# EFR32FG1V131F256GM48 register map
File version: 3.0.0
CPU: CM4 r0p1, little endian, MPU, FPU, 3 interrupt priority bits
Registers are 32-bit, read-write, reset 0x0 unless marked. A register's access mark holds for its fields unless they carry their own. Offsets are from the block's base; [hi:lo] are bit positions; {n}, {i} and the like mark numbered series; 'fields as' and 'values as' point back to an identical list.

## RAC — Radio controller
Base 0x40084000
Same registers: RAC_CLR 0x44084000, RAC_SET 0x46084000
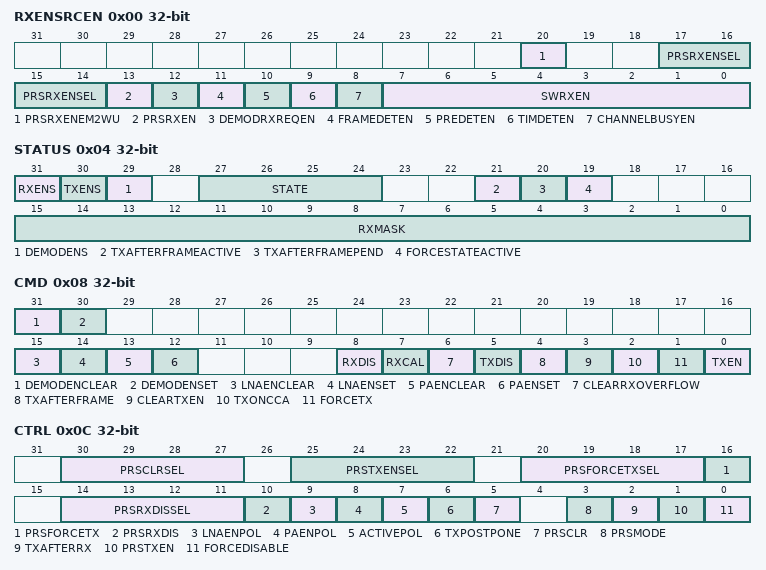
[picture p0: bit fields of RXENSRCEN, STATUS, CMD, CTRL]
0x00 RXENSRCEN
  [20] PRSRXENEM2WU, [17:14] PRSRXENSEL, [13] PRSRXEN, [12] DEMODRXREQEN, [11] FRAMEDETEN, [10] PREDETEN, [9] TIMDETEN, [8] CHANNELBUSYEN, [7:0] SWRXEN
0x04 STATUS ro
  [31] RXENS, [30] TXENS, [29] DEMODENS, [27:24] STATE, [21] TXAFTERFRAMEACTIVE, [20] TXAFTERFRAMEPEND, [19] FORCESTATEACTIVE, [15:0] RXMASK
0x08 CMD wo (reset mask 0x13FFFF)
  [31] DEMODENCLEAR, [30] DEMODENSET, [15] LNAENCLEAR, [14] LNAENSET, [13] PAENCLEAR, [12] PAENSET, [8] RXDIS, [7] RXCAL, [6] CLEARRXOVERFLOW, [5] TXDIS, [4] TXAFTERFRAME, [3] CLEARTXEN, [2] TXONCCA, [1] FORCETX, [0] TXEN
0x0C CTRL
  [30:27] PRSCLRSEL, [25:22] PRSTXENSEL, [20:17] PRSFORCETXSEL, [16] PRSFORCETX, [14:11] PRSRXDISSEL, [10] PRSRXDIS, [9] LNAENPOL, [8] PAENPOL, [7] ACTIVEPOL, [6] TXPOSTPONE, [5] PRSCLR, [3] PRSMODE, [2] TXAFTERRX, [1] PRSTXEN, [0] FORCEDISABLE
0x10 FORCESTATE
  [3:0] FORCESTATE
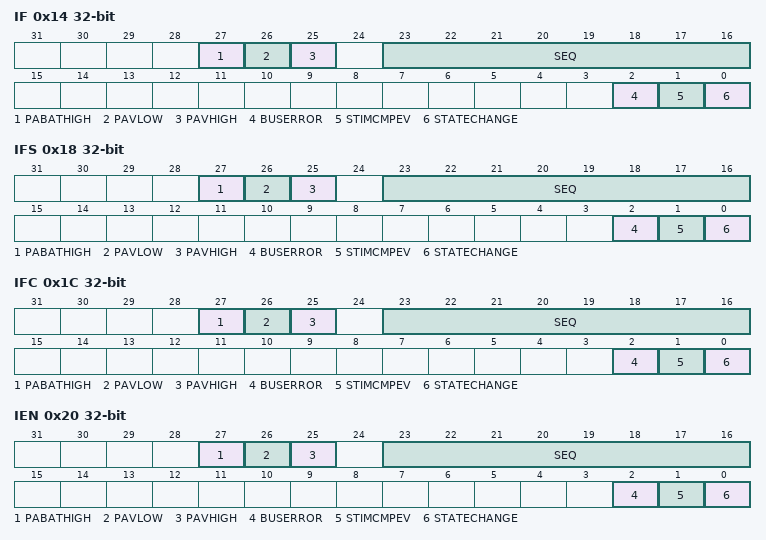
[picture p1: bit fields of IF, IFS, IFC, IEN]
0x14 IF ro
  [27] PABATHIGH, [26] PAVLOW, [25] PAVHIGH, [23:16] SEQ, [2] BUSERROR, [1] STIMCMPEV, [0] STATECHANGE
0x18 IFS wo
  fields as IF
0x1C IFC wo
  fields as IF
0x20 IEN
  fields as IF
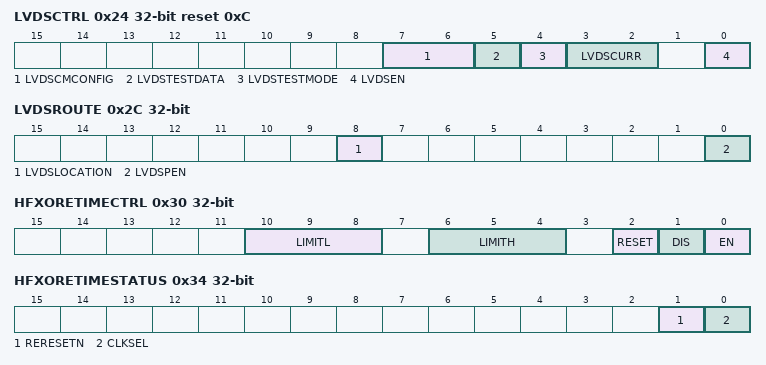
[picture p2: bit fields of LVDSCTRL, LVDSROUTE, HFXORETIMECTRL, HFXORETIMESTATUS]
0x24 LVDSCTRL reset 0xC
  [7:6] LVDSCMCONFIG, [5] LVDSTESTDATA, [4] LVDSTESTMODE, [3:2] LVDSCURR, [0] LVDSEN
0x28 LVDSIDLESEQ reset 0xBC
  [7:0] LVDSIDLESEQ
0x2C LVDSROUTE
  [8] LVDSLOCATION, [0] LVDSPEN
0x30 HFXORETIMECTRL
  [10:8] LIMITL, [6:4] LIMITH, [2] RESET, [1] DIS, [0] EN
0x34 HFXORETIMESTATUS ro
  [1] RERESETN, [0] CLKSEL
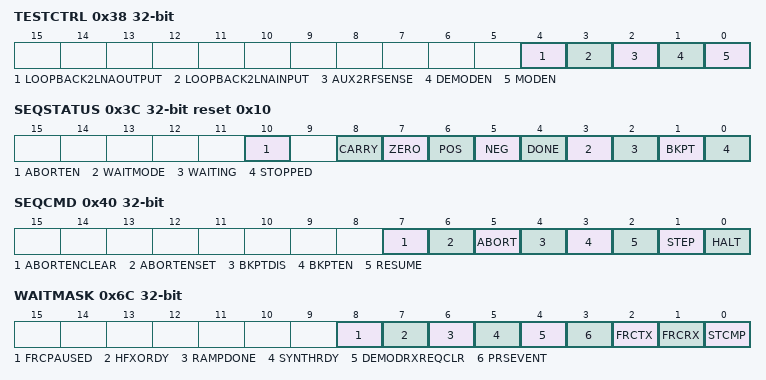
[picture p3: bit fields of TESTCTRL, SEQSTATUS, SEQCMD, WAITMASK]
0x38 TESTCTRL
  [4] LOOPBACK2LNAOUTPUT, [3] LOOPBACK2LNAINPUT, [2] AUX2RFSENSE, [1] DEMODEN, [0] MODEN
0x3C SEQSTATUS ro reset 0x10
  [10] ABORTEN, [8] CARRY, [7] ZERO, [6] POS, [5] NEG, [4] DONE, [3] WAITMODE, [2] WAITING, [1] BKPT, [0] STOPPED
0x40 SEQCMD wo
  [7] ABORTENCLEAR, [6] ABORTENSET, [5] ABORT, [4] BKPTDIS, [3] BKPTEN, [2] RESUME, [1] STEP, [0] HALT
0x44 BREAKPOINT
  [31:0] BKPADDR
{0x48+4i} R{i} (i=0..7)
0x6C WAITMASK ro
  [8] FRCPAUSED, [7] HFXORDY, [6] RAMPDONE, [5] SYNTHRDY, [4] DEMODRXREQCLR, [3] PRSEVENT, [2] FRCTX, [1] FRCRX, [0] STCMP
0x70 WAITSNSH ro
  [9:0] WAITSNSH
0x74 STIMER ro
  [15:0] STIMER
0x78 STIMERCOMP
  [15:0] STIMERCOMP
0x7C VECTADDR
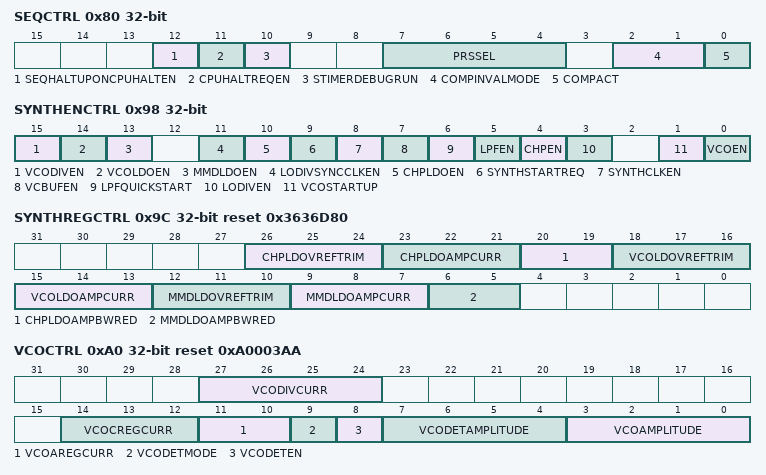
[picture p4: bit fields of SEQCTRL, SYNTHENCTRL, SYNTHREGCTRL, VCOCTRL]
0x80 SEQCTRL
  [12] SEQHALTUPONCPUHALTEN, [11] CPUHALTREQEN, [10] STIMERDEBUGRUN, [7:4] PRSSEL, [2:1] COMPINVALMODE, [0] COMPACT
0x84 PRESC reset 0x7
  [6:0] STIMER
{0x88+4i} SR{i} (i=0..3)
0x98 SYNTHENCTRL
  [15] VCODIVEN, [14] VCOLDOEN, [13] MMDLDOEN, [11] LODIVSYNCCLKEN, [10] CHPLDOEN, [9] SYNTHSTARTREQ, [8] SYNTHCLKEN, [7] VCBUFEN, [6] LPFQUICKSTART, [5] LPFEN, [4] CHPEN, [3] LODIVEN, [1] VCOSTARTUP, [0] VCOEN
0x9C SYNTHREGCTRL reset 0x3636D80
  [26:24] CHPLDOVREFTRIM, [23:21] CHPLDOAMPCURR, [20:19] CHPLDOAMPBWRED, [18:16] VCOLDOVREFTRIM, [15:13] VCOLDOAMPCURR, [12:10] MMDLDOVREFTRIM, [9:7] MMDLDOAMPCURR, [6:5] MMDLDOAMPBWRED
0xA0 VCOCTRL reset 0xA0003AA
  [27:24] VCODIVCURR, [14:12] VCOCREGCURR, [11:10] VCOAREGCURR, [9] VCODETMODE, [8] VCODETEN, [7:4] VCODETAMPLITUDE, [3:0] VCOAMPLITUDE
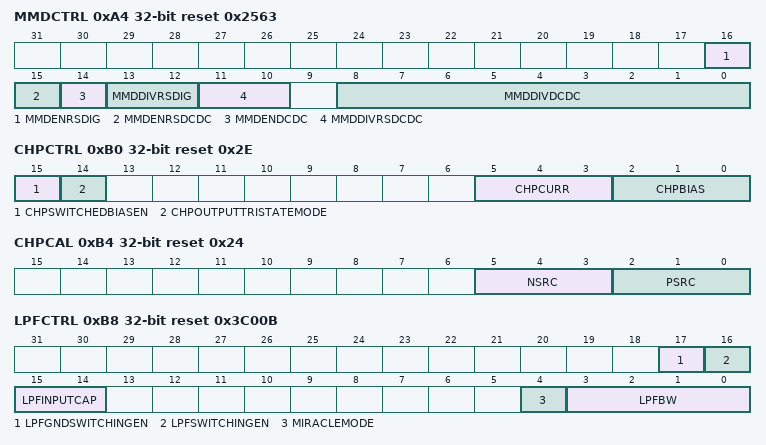
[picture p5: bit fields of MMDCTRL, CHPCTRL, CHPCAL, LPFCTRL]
0xA4 MMDCTRL reset 0x2563
  [16] MMDENRSDIG, [15] MMDENRSDCDC, [14] MMDENDCDC, [13:12] MMDDIVRSDIG, [11:10] MMDDIVRSDCDC, [8:0] MMDDIVDCDC
0xB0 CHPCTRL reset 0x2E
  [15] CHPSWITCHEDBIASEN, [14] CHPOUTPUTTRISTATEMODE, [5:3] CHPCURR, [2:0] CHPBIAS
0xB4 CHPCAL reset 0x24
  [5:3] NSRC, [2:0] PSRC
0xB8 LPFCTRL reset 0x3C00B
  [17] LPFGNDSWITCHINGEN, [16] LPFSWITCHINGEN, [15:14] LPFINPUTCAP, [4] MIRACLEMODE, [3:0] LPFBW
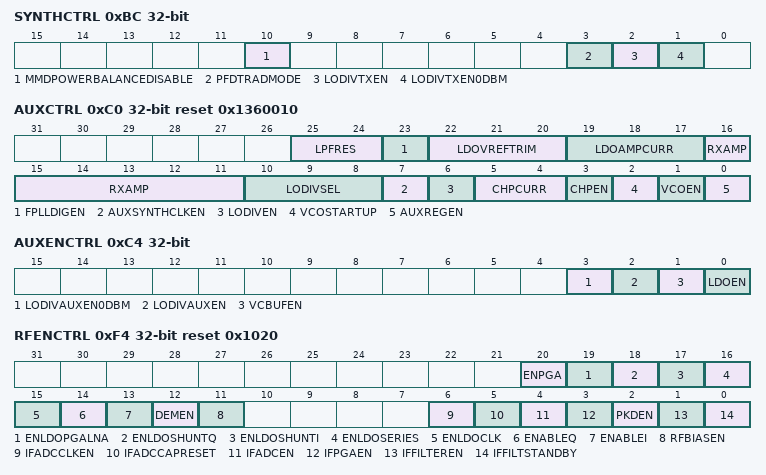
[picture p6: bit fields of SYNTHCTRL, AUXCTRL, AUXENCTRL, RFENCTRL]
0xBC SYNTHCTRL
  [10] MMDPOWERBALANCEDISABLE, [3] PFDTRADMODE, [2] LODIVTXEN, [1] LODIVTXEN0DBM
0xC0 AUXCTRL reset 0x1360010
  [25:24] LPFRES, [23] FPLLDIGEN, [22:20] LDOVREFTRIM, [19:17] LDOAMPCURR, [16:11] RXAMP, [10:8] LODIVSEL, [7] AUXSYNTHCLKEN, [6] LODIVEN, [5:4] CHPCURR, [3] CHPEN, [2] VCOSTARTUP, [1] VCOEN, [0] AUXREGEN
0xC4 AUXENCTRL
  [3] LODIVAUXEN0DBM, [2] LODIVAUXEN, [1] VCBUFEN, [0] LDOEN
0xF4 RFENCTRL reset 0x1020
  [20] ENPGA, [19] ENLDOPGALNA, [18] ENLDOSHUNTQ, [17] ENLDOSHUNTI, [16] ENLDOSERIES, [15] ENLDOCLK, [14] ENABLEQ, [13] ENABLEI, [12] DEMEN, [11] RFBIASEN, [6] IFADCCLKEN, [5] IFADCCAPRESET, [4] IFADCEN, [3] IFPGAEN, [2] PKDEN, [1] IFFILTEREN, [0] IFFILTSTANDBY
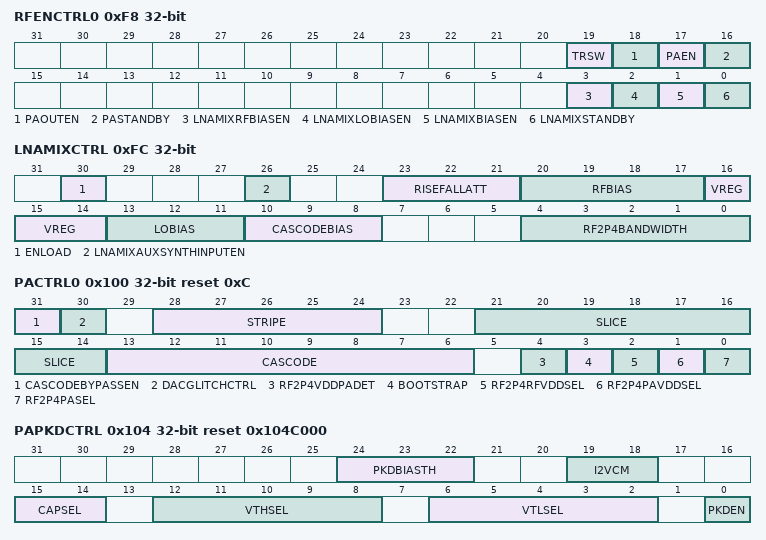
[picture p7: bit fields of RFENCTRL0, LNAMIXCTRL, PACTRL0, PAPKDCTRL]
0xF8 RFENCTRL0
  [19] TRSW, [18] PAOUTEN, [17] PAEN, [16] PASTANDBY, [3] LNAMIXRFBIASEN, [2] LNAMIXLOBIASEN, [1] LNAMIXBIASEN, [0] LNAMIXSTANDBY
0xFC LNAMIXCTRL
  [30] ENLOAD, [26] LNAMIXAUXSYNTHINPUTEN, [23:21] RISEFALLATT, [20:17] RFBIAS, [16:14] VREG, [13:11] LOBIAS, [10:8] CASCODEBIAS, [4:0] RF2P4BANDWIDTH
0x100 PACTRL0 reset 0xC
  [31] CASCODEBYPASSEN, [30] DACGLITCHCTRL, [28:24] STRIPE, [21:14] SLICE, [13:6] CASCODE, [4] RF2P4VDDPADET, [3] BOOTSTRAP, [2] RF2P4RFVDDSEL, [1] RF2P4PAVDDSEL, [0] RF2P4PASEL
0x104 PAPKDCTRL reset 0x104C000
  [24:22] PKDBIASTH, [19:18] I2VCM, [15:14] CAPSEL, [12:8] VTHSEL, [6:2] VTLSEL, [0] PKDEN
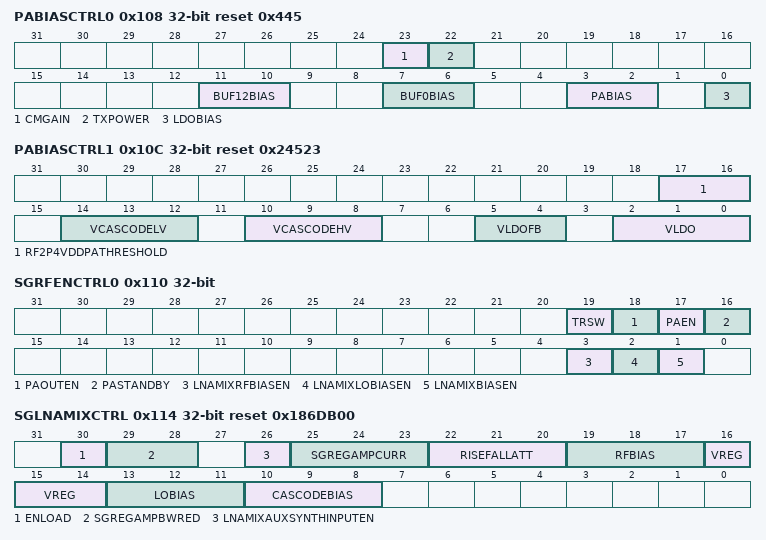
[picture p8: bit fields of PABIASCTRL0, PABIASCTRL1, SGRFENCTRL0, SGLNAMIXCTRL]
0x108 PABIASCTRL0 reset 0x445
  [23] CMGAIN, [22] TXPOWER, [11:10] BUF12BIAS, [7:6] BUF0BIAS, [3:2] PABIAS, [0] LDOBIAS
0x10C PABIASCTRL1 reset 0x24523
  [17:16] RF2P4VDDPATHRESHOLD, [14:12] VCASCODELV, [10:8] VCASCODEHV, [5:4] VLDOFB, [2:0] VLDO
0x110 SGRFENCTRL0
  [19] TRSW, [18] PAOUTEN, [17] PAEN, [16] PASTANDBY, [3] LNAMIXRFBIASEN, [2] LNAMIXLOBIASEN, [1] LNAMIXBIASEN
0x114 SGLNAMIXCTRL reset 0x186DB00
  [30] ENLOAD, [29:28] SGREGAMPBWRED, [26] LNAMIXAUXSYNTHINPUTEN, [25:23] SGREGAMPCURR, [22:20] RISEFALLATT, [19:17] RFBIAS, [16:14] VREG, [13:11] LOBIAS, [10:8] CASCODEBIAS
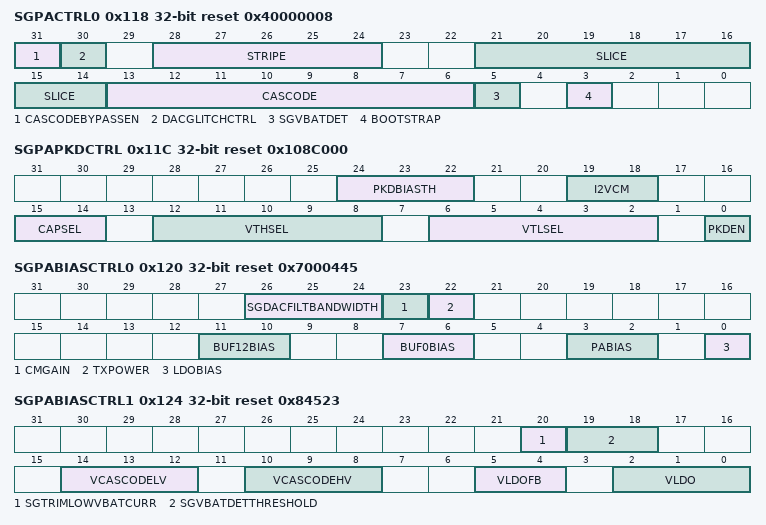
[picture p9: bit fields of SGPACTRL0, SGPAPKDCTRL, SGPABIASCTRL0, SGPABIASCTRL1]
0x118 SGPACTRL0 reset 0x40000008
  [31] CASCODEBYPASSEN, [30] DACGLITCHCTRL, [28:24] STRIPE, [21:14] SLICE, [13:6] CASCODE, [5] SGVBATDET, [3] BOOTSTRAP
0x11C SGPAPKDCTRL reset 0x108C000
  fields as PAPKDCTRL
0x120 SGPABIASCTRL0 reset 0x7000445
  [26:24] SGDACFILTBANDWIDTH, [23] CMGAIN, [22] TXPOWER, [11:10] BUF12BIAS, [7:6] BUF0BIAS, [3:2] PABIAS, [0] LDOBIAS
0x124 SGPABIASCTRL1 reset 0x84523
  [20] SGTRIMLOWVBATCURR, [19:18] SGVBATDETTHRESHOLD, [14:12] VCASCODELV, [10:8] VCASCODEHV, [5:4] VLDOFB, [2:0] VLDO
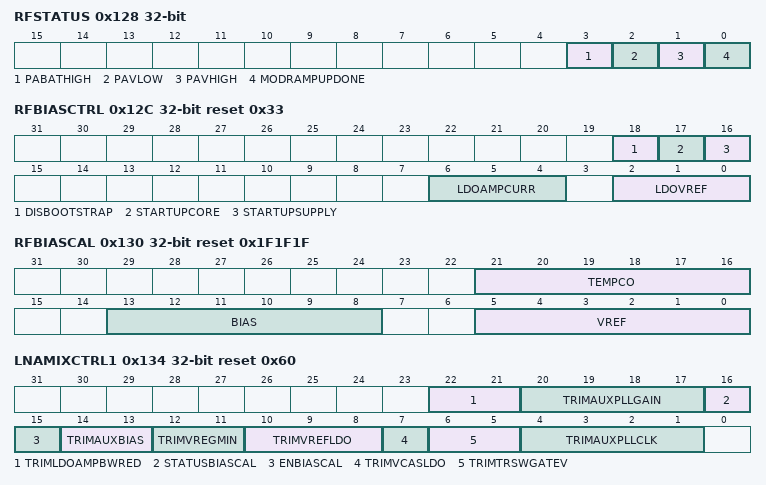
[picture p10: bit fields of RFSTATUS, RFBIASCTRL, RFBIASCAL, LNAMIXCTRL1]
0x128 RFSTATUS ro
  [3] PABATHIGH, [2] PAVLOW, [1] PAVHIGH, [0] MODRAMPUPDONE
0x12C RFBIASCTRL reset 0x33
  [18] DISBOOTSTRAP, [17] STARTUPCORE, [16] STARTUPSUPPLY, [6:4] LDOAMPCURR, [2:0] LDOVREF
0x130 RFBIASCAL reset 0x1F1F1F
  [21:16] TEMPCO, [13:8] BIAS, [5:0] VREF
0x134 LNAMIXCTRL1 reset 0x60
  [22:21] TRIMLDOAMPBWRED, [20:17] TRIMAUXPLLGAIN, [16] STATUSBIASCAL, [15] ENBIASCAL, [14:13] TRIMAUXBIAS, [12:11] TRIMVREGMIN, [10:8] TRIMVREFLDO, [7] TRIMVCASLDO, [6:5] TRIMTRSWGATEV, [4:1] TRIMAUXPLLCLK
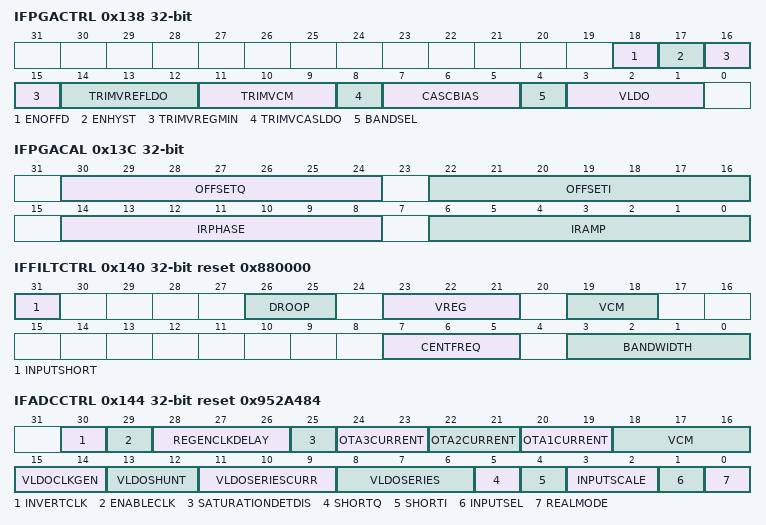
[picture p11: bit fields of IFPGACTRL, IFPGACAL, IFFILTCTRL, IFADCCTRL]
0x138 IFPGACTRL
  [18] ENOFFD, [17] ENHYST, [16:15] TRIMVREGMIN, [14:12] TRIMVREFLDO, [11:9] TRIMVCM, [8] TRIMVCASLDO, [7:5] CASCBIAS, [4] BANDSEL, [3:1] VLDO
0x13C IFPGACAL
  [30:24] OFFSETQ, [22:16] OFFSETI, [14:8] IRPHASE, [6:0] IRAMP
0x140 IFFILTCTRL reset 0x880000
  [31] INPUTSHORT, [26:25] DROOP, [23:21] VREG, [19:18] VCM, [7:5] CENTFREQ, [3:0] BANDWIDTH
0x144 IFADCCTRL reset 0x952A484
  [30] INVERTCLK, [29] ENABLECLK, [28:26] REGENCLKDELAY, [25] SATURATIONDETDIS, [24:23] OTA3CURRENT, [22:21] OTA2CURRENT, [20:19] OTA1CURRENT, [18:16] VCM, [15:14] VLDOCLKGEN, [13:12] VLDOSHUNT, [11:9] VLDOSERIESCURR, [8:6] VLDOSERIES, [5] SHORTQ, [4] SHORTI, [3:2] INPUTSCALE, [1] INPUTSEL, [0] REALMODE
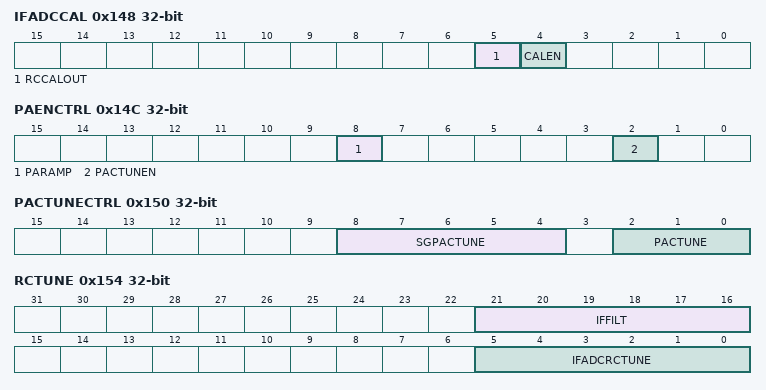
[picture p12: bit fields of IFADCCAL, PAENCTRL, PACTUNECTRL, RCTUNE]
0x148 IFADCCAL
  [5] RCCALOUT ro, [4] CALEN
0x14C PAENCTRL
  [8] PARAMP, [2] PACTUNEN
0x150 PACTUNECTRL
  [8:4] SGPACTUNE, [2:0] PACTUNE
0x154 RCTUNE
  [21:16] IFFILT, [5:0] IFADCRCTUNE
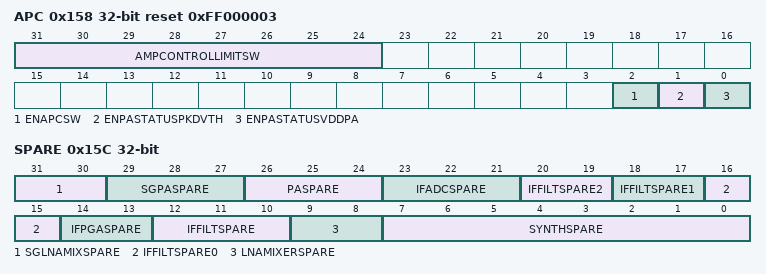
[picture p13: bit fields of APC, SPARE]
0x158 APC reset 0xFF000003
  [31:24] AMPCONTROLLIMITSW, [2] ENAPCSW, [1] ENPASTATUSPKDVTH, [0] ENPASTATUSVDDPA
0x15C SPARE
  [31:30] SGLNAMIXSPARE, [29:27] SGPASPARE, [26:24] PASPARE, [23:21] IFADCSPARE, [20:19] IFFILTSPARE2, [18:17] IFFILTSPARE1, [16:15] IFFILTSPARE0, [14:13] IFPGASPARE, [12:10] IFFILTSPARE, [9:8] LNAMIXERSPARE, [7:0] SYNTHSPARE
